# haltium_sysctrl register map
Vendor: Nordic Semiconductor; Series: nRFHaltium; File version: 1
Registers are 32-bit, read-write, reset 0x0 unless marked. A register's access mark holds for its fields unless they carry their own. Offsets are from the block's base; [hi:lo] are bit positions; {n}, {i} and the like mark numbered series; 'fields as' and 'values as' point back to an identical list.

## GRAMC00_S — RAM Controller 0
Base 0x5F083000
Same registers: GRAMC01_S 0x5F084000, GRAMC10_S 0x5F8C3000, GRAMC11_S 0x5F8C4000, GROMC00_S 0x5F8C6000, GRAMC20_S 0x5F903000, GRAMC21_S 0x5F904000
0x100 EVENTS_ERRORFIX — ECC detected fixable (one bit) error in read data from RAM.
  [0] EVENTS_ERRORFIX
    0=NotGenerated (Event not generated); 1=Generated (Event generated)
0x104 EVENTS_ERRORNONFIX — ECC detected non-fixable (multiple bits) error in read data from RAM.
  [0] EVENTS_ERRORNONFIX
    values as EVENTS_ERRORFIX.EVENTS_ERRORFIX
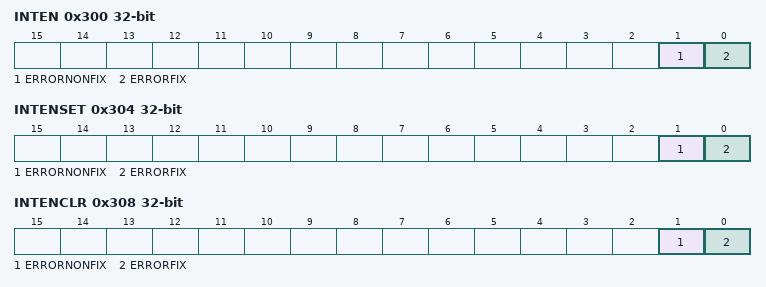
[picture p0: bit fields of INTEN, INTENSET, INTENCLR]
0x300 INTEN — Enable or disable interrupt
  [1] ERRORNONFIX — Enable or disable interrupt for event ERRORNONFIX
    0=Disabled; 1=Enabled
  [0] ERRORFIX — Enable or disable interrupt for event ERRORFIX
    0=Disabled; 1=Enabled
0x304 INTENSET — Enable interrupt
  [1] ERRORNONFIX — Write '1' to enable interrupt for event ERRORNONFIX
    on read: 0=Disabled (Read: Disabled); 1=Enabled (Read: Enabled) | on write: 1=Set (Enable)
  [0] ERRORFIX — Write '1' to enable interrupt for event ERRORFIX
    values as ERRORNONFIX
0x308 INTENCLR — Disable interrupt
  [1] ERRORNONFIX — Write '1' to disable interrupt for event ERRORNONFIX
    on read: 0=Disabled (Read: Disabled); 1=Enabled (Read: Enabled) | on write: 1=Clear (Disable)
  [0] ERRORFIX — Write '1' to disable interrupt for event ERRORFIX
    values as ERRORNONFIX
0x400 FIXADDR ro — Address of the last fixable error detected by the ECC.
  [31:0] ADDR — Address of the last fixable error.
0x404 NONFIXADDR ro — Address of the last non-fixable error detected by the ECC.
  [31:0] ADDR — Address of the last fixable error.
0x500 WAITSTATES — Waitstates for read.
  [2:0] WAITSTATES — Waitstates for read from RAM or ROM.
0x600 SECBASE — Base address for secure access area.
  [31:0] ADDR — Base address
0x604 SECENABLE — Enable secure access restrictions.
  [0] ENABLE — Enable secure access restrictions
    0=Disable (Secure access restrictions disabled); 1=Enable (Secure access restrictions enabled)

## EXMIF_NS — External Memory Interface 0
Base 0x4F095000
Same registers: EXMIF_S 0x5F095000
0x00 TASKS_START wo — Start operation.
  [0] TASKS_START
    1=Trigger task
0x04 TASKS_STOP wo — Stop operation.
  [0] TASKS_STOP
    1=Trigger task
0x400 ADDRESS1LO — The address mapping definition for external memory device 1.
  [31:0] OFFSET — External memory Offset.
0x404 ADDRESS1HI reset 0xFFFFFFF — Upper address range definition for external memory device 1.
  [31:0] ADDRESS — Upper limit address.
0x408 ADDRESS2LO reset 0x10000000 — The address mapping definition for external memory device 2.
  [31:0] OFFSET — External memory Offset.
0x40C ADDRESS2HI reset 0x1FFFFFFF — Upper address range definition for external memory device 2.
  [31:0] ADDRESS — Upper limit address.
0x410 EXTMEMEN — Enable or disable external memory access.
  [0] ENABLE — Enable or disable external memory access from AXI interface.
    0=Disabled (Disable external memory.); 1=Enabled (Enable external memory.)
0x414 LOCKEDACCESS — Enable or disable locked APB access to serial memory controller.
  [0] ENABLE — Enable or disable locked APB access to SSI.
    0=Disabled (Disable locked APB access.); 1=Enabled (Enable locked APB access.)
0x418 PROGDELAY reset 0x7 — Configures delay of the incoming data strobe.
  [3:0] DELAY — Delay value.
    0=NoDelay; 1=Delay250ps (Delay is 250 ps.); 2=Delay500ps (Delay is 500 ps.); 3=Delay750ps (Delay is 750 ps.); 4=Delay1000ps (Delay is 1 ns.); 5=Delay1250ps (Delay is 1.25 ns.); 6=Delay1500ps (Delay is 1.50 ns.); 7=Delay1750ps (Delay is 1.75 ns.); 8=Delay2000ps (Delay is 2 ns.); 9=Delay2250ps (Delay is 2.25 ns.); 10=Delay2500ps (Delay is 2.50 ns.); 11=Delay2750ps (Delay is 2.75 ns.); 12=Delay3000ps (Delay is 3 ns.)
0x41C RESET — Reset the external memory.
  [0] RESET
    0=Clear (Reset is cleared.); 1=Set (Reset is set.)
0x420 EXTMEM2 reset 0x1 — Enable external memory 2.
  [0] ENABLE
    0=Disabled (Disable external memory 2.); 1=Enabled (Enable external memory 2.)
{0x500+4i} REGISTER[{i}] (i=0..72) — Description collection: SSI Registers.
  [31:0] FIELD — Fields for REGISTER[n]
